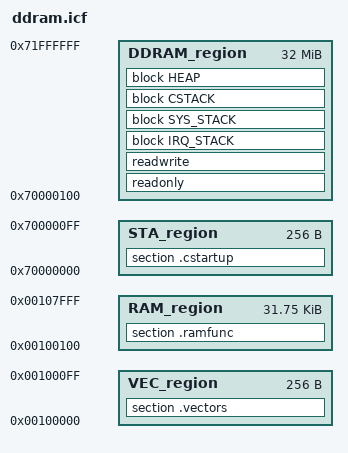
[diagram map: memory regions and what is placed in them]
/*###ICF### Section handled by ICF editor, don't touch! ****/
/*-Editor annotation file-*/
/* IcfEditorFile="$TOOLKIT_DIR$\config\ide\IcfEditor\a_v1_0.xml" */
/*-Memory Regions-*/
define symbol __ICFEDIT_region_DDRAM_start__ = 0x70000000;
define symbol __ICFEDIT_region_DDRAM_end__   = 0x71FFFFFF;
define symbol __ICFEDIT_region_RAM_start__   = 0x100000;
define symbol __ICFEDIT_region_RAM_end__     = 0x107fff;
/*-Sizes-*/
define symbol __ICFEDIT_size_startup__  = 0x100;
define symbol __ICFEDIT_size_vectors__  = 0x100;
define symbol __ICFEDIT_size_cstack__   = 0x1000;
define symbol __ICFEDIT_size_sysstack__ = 0x60;
define symbol __ICFEDIT_size_irqstack__ = 0x60;
define symbol __ICFEDIT_size_heap__     = 0x0;
/**** End of ICF editor section. ###ICF###*/

define memory mem with size = 4G;
define region VEC_region = mem:[from __ICFEDIT_region_RAM_start__ size __ICFEDIT_size_vectors__];
define region RAM_region = mem:[from __ICFEDIT_region_RAM_start__+__ICFEDIT_size_vectors__ to __ICFEDIT_region_RAM_end__];
define region STA_region = mem:[from __ICFEDIT_region_DDRAM_start__ size __ICFEDIT_size_startup__];
define region DDRAM_region = mem:[from __ICFEDIT_region_DDRAM_start__+__ICFEDIT_size_startup__ to __ICFEDIT_region_DDRAM_end__];

define block CSTACK    with alignment = 8, size = __ICFEDIT_size_cstack__   { };
define block SYS_STACK with alignment = 8, size = __ICFEDIT_size_sysstack__ { };
define block IRQ_STACK with alignment = 8, size = __ICFEDIT_size_irqstack__ { };
define block HEAP      with alignment = 8, size = __ICFEDIT_size_heap__ { };

initialize by copy { section .vectors };
initialize by copy { section .ramfunc };
do not initialize  { section .noinit };

place in STA_region { section .cstartup };
place in VEC_region { section .vectors };
place in RAM_region { section .ramfunc };
place in DDRAM_region { readonly, readwrite, block IRQ_STACK, block SYS_STACK, block CSTACK, block HEAP };
